# XMC4800 register map
Vendor: Infineon; File version: 1.3.0 (Reference Manual v1.3)
CPU: CM4 r2p0, little endian, MPU, FPU, 6 interrupt priority bits
Registers are 32-bit, read-write, reset 0x0 unless marked. A register's access mark holds for its fields unless they carry their own. Offsets are from the block's base; [hi:lo] are bit positions; {n}, {i} and the like mark numbered series; 'fields as' and 'values as' point back to an identical list.

## EBU — External Bus Unit
Base 0x58008000
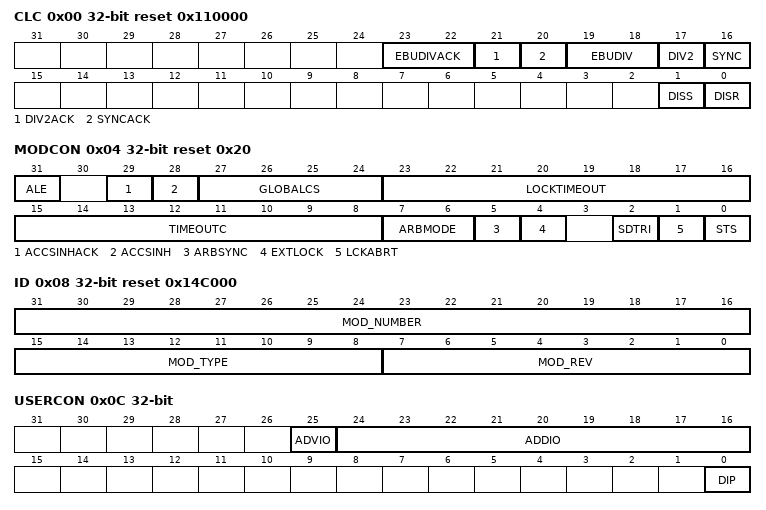
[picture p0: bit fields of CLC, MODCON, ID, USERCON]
0x00 CLC access per field reset 0x110000 — EBU Clock Control Register
  [23:22] EBUDIVACK ro — EBU Clock Divide Ratio Status
    0=EBU is running off input clock (default after reset); 1=EBU is running off input clock divided by 2; 2=EBU is running off input clock divided by 3; 3=EBU is running off input clock divided by 4
  [21] DIV2ACK ro — DIV2 Clocking Mode Status
    0=EBU is using standard clocking mode. clock input selected by SYNC bitfield (default after reset).; 1=EBU is running off AHB bus clock divided by 2
  [20] SYNCACK ro — EBU Clocking Mode Status
    0=the EBU is asynchronous to the AHB bus clock and is using a separate clock source; 1=EBU is synchronous to the AHB bus clock (default after reset)
  [19:18] EBUDIV rw — EBU Clock Divide Ratio
    0=request EBU to run off input clock (default after reset); 1=request EBU to run off input clock divided by 2; 2=request EBU to run off input clock divided by 3; 3=request EBU to run off input clock divided by 4
  [17] DIV2 rw — DIV2 Clocking Mode
    0=standard clocking mode. clock input selected by SYNC bitfield (default after reset).; 1=request EBU to run off AHB bus clock divided by 2
  [16] SYNC rw — EBU Clocking Mode
    0=request EBU to run asynchronously to AHB bus clock and use separate clock source; 1=request EBU to run synchronously to ARM processor (default after reset)
  [1] DISS ro — EBU Disable Status Bit
    0=EBU is enabled (default after reset); 1=EBU is disabled
  [0] DISR rw — EBU Disable Request Bit
    0=EBU disable is not requested; 1=EBU disable is requested
0x04 MODCON access per field reset 0x20 — EBU Configuration Register
  [31] ALE rw — ALE Mode
    0=Output is ADV; 1=Output is ALE
  [29] ACCSINHACK ro — Access inhibit acknowledge
  [28] ACCSINH rw — Access Inhibit request
  [27:24] GLOBALCS rw — Global Chip Select Enable
  [23:16] LOCKTIMEOUT rw — Lock Timeout Counter Preload
  [15:8] TIMEOUTC rw — Bus Time-out Control
    0=Time-out is disabled; 1=Time-out is generated after 1 8 clock cycles; 255=Time-out is generated after 255 8 clock cycles
  [7:6] ARBMODE rw — Arbitration Mode Selection
    0=No Bus arbitration mode selected; 1=Arbiter Mode arbitration mode selected; 2=Participant arbitration mode selected; 3=Sole Master arbitration mode selected
  [5] ARBSYNC rw — Arbitration Signal Synchronization Control
    0=Arbitration inputs are synchronous; 1=Arbitration inputs are asynchronous
  [4] EXTLOCK rw — External Bus Lock Control
    0=External bus is not locked after the EBU gains ownership; 1=External bus is locked after the EBU gains ownership
  [2] SDTRI rw — SDRAM Tristate
    0=SDRAM control signals are driven by the EBU when the EBU does not own the external bus. SDRAM cannot be shared.; 1=SDRAM control signals are tri-stated by the EBU when the EBU does not own the external bus. The SDRAM can be shared.
  [1] LCKABRT ro — Lock Abort
  [0] STS ro — Memory Status Bit
0x08 ID ro reset 0x14C000 (reset mask 0xFFFFFF00) — EBU Module Identification Register
  [31:16] MOD_NUMBER — Module Number
  [15:8] MOD_TYPE — Module Type
  [7:0] MOD_REV — Module Revision
0x0C USERCON — EBU Test/Control Configuration Register
  [25] ADVIO — ADV Pin to GPIO Mode
    0=ADV pin is required for controlling memory; 1=ADV pin is available for GPIO function
  [24:16] ADDIO — Address Pins to GPIO Mode
    0=Address Bit is required for addressing memory; 1=Address Bit is available for GPIO function
  [0] DIP — Disable Internal Pipelining
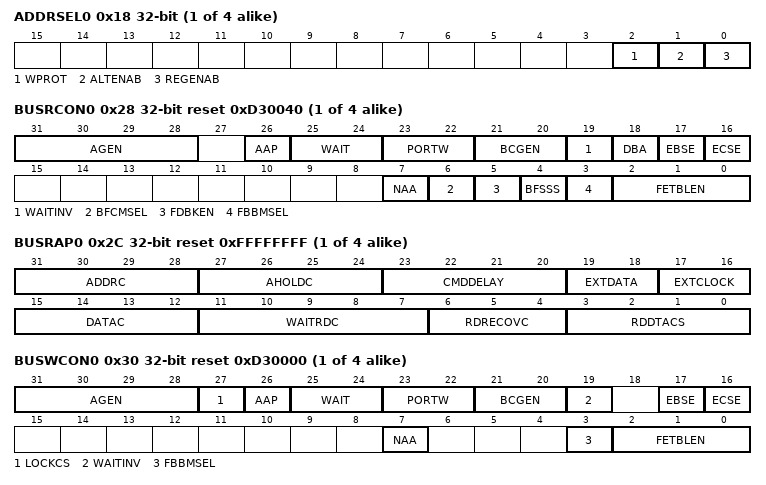
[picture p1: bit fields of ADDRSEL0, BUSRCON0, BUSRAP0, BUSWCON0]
{0x18+4i} ADDRSEL{i} (i=0..3) — EBU Address Select Register {i}
  [2] WPROT — Memory Region Write Protect
    0=Region is enabled for write accesses; 1=Region is write protected
  [1] ALTENAB — Alternate Region Enable
    0=Memory region is disabled (default after reset); 1=Memory region is enabled
  [0] REGENAB — Memory Region Enable
    values as ALTENAB
{0x28+0x10*i} BUSRCON{i} reset 0xD30040 (i=0..3) — EBU Bus Configuration Register
  [31:28] AGEN — Device Type for Region
  [26] AAP — Asynchronous Address phase:
    0=Clock is enabled at beginning of access; 1=Clock is enabled at after address phase
  [25:24] WAIT — External Wait Control: 0=OFF (default after reset)., 1=Asynchronous input at WAIT., 2=Synchronous input at WAIT., 3=reserved., 0=OFF (default after reset)., 1=Wait for page load (Early WAIT)., 2=Wait for page load (WAIT with data)., 3=Abort and retry access.,
  [23:22] PORTW — Device Addressing Mode
  [21:20] BCGEN — Byte Control Signal Control
    0=Byte control signals follow chip select timing; 1=Byte control signals follow control signal timing (RD, RD/WR) (default after reset); 2=Byte control signals follow write enable signal timing (RD/WR only)
  [19] WAITINV — Reversed polarity at WAIT
    0=input at WAIT pin is active low (default after reset); 1=input at WAIT pin is active high
  [18] DBA — Disable Burst Address Wrapping
    0=Memory Controller automatically re-aligns any non-aligned synchronous burst access so that data can be fetched from the device in a single burst transaction; 1=Memory Controller always starts any burst access to a synchronous burst device at the address specified by the AHB request. Any required address wrapping must be automatically provided by the Burst FLASH device.
  [17] EBSE — Early Burst Signal Enable for Synchronous Burst
    0=ADV is delayed; 1=ADV is not delayed
  [16] ECSE — Early Chip Select for Synchronous Burst
    0=CS is delayed; 1=CS is not delayed
  [7] NAA — Enable flash non-array access workaround
  [6] BFCMSEL — Burst Flash Clock Mode Select
    0=Burst Flash Clock runs continuously with values selected by this register; 1=Burst Flash Clock is disabled between accesses
  [5] FDBKEN — Burst FLASH Clock Feedback Enable
    0=BFCLK feedback not used; 1=Incoming data and control signals (from the Burst FLASH device) are re-synchronized to the BFCLKI input
  [4] BFSSS — Read Single Stage Synchronization:
    0=Two stages of synchronization used. (maximum margin); 1=One stage of synchronization used. (minimum latency)
  [3] FBBMSEL — Synchronous burst buffer mode select
    0=Burst buffer length defined by value in FETBLEN (default after reset); 1=Continuous mode. All data required for transaction is transferred in a single burst.
  [2:0] FETBLEN — Burst Length for Synchronous Burst
    0=1 data access (default after reset); 1=2 data accesses; 2=4 data accesses; 3=8 data accesses
{0x2C+0x10*i} BUSRAP{i} reset 0xFFFFFFFF (i=0..3) — EBU Bus Read Access Parameter Register
  [31:28] ADDRC — Address Cycles
    0=1 clock cycle selected; 1=1 clock cycle selected; 14=14 clock cycles selected; 15=15 clock cycles selected
  [27:24] AHOLDC — Address Hold Cycles
    0=0 clock cycle selected; 1=1 clock cycle selected; 14=14 clock cycles selected; 15=15 clock cycles selected
  [23:20] CMDDELAY — Command Delay Cycles
    values as AHOLDC
  [19:18] EXTDATA — Extended data
    0=external memory outputs data every BFCLK cycle; 1=external memory outputs data every two BFCLK cycles; 2=external memory outputs data every four BFCLK cycles; 3=external memory outputs data every eight BFCLK cycles
  [17:16] EXTCLOCK — Frequency of external clock at pin BFCLKO
    0=Equal to INT_CLK frequency; 1=1/2 of INT_CLK frequency; 2=1/3 of INT_CLK frequency; 3=1/4 of INT_CLK frequency (default after reset)
  [15:12] DATAC — Data Hold Cycles for Read Accesses
  [11:7] WAITRDC — Programmed Wait States for read accesses
    0=1 wait state; 1=1 wait states; 2=2 wait state; 30=30 wait states; 31=31 wait states
  [6:4] RDRECOVC — Recovery Cycles after Read Accesses
    0=No Recovery Phase clock cycles available; 1=1 clock cycle selected; 6=6 clock cycles selected; 7=7 clock cycles selected
  [3:0] RDDTACS — Recovery Cycles between Different Regions
    0=No Recovery Phase clock cycles available; 1=1 clock cycle selected; 14=14 clock cycles selected; 15=15 clock cycles selected
{0x30+0x10*i} BUSWCON{i} access per field reset 0xD30000 (i=0..3) — EBU Bus Write Configuration Register
  [31:28] AGEN rw — Device Type for Region
  [27] LOCKCS rw — Lock Chip Select
    0=Chip Select cannot be locked (default after reset); 1=Chip Select will be automatically locked when written to from the processor data port
  [26] AAP rw — Asynchronous Address phase:
    values as BUSRCON0.AAP
  [25:24] WAIT rw — External Wait Control: 0=OFF (default after reset)., 1=Asynchronous input at WAIT., 2=Synchronous input at WAIT., 3=reserved., 0=OFF (default after reset)., 1=Wait for page load (Early WAIT)., 2=Wait for page load (WAIT with data)., 3=Abort and retry access.,
  [23:22] PORTW ro — Device Addressing Mode
  [21:20] BCGEN rw — Byte Control Signal Control
    values as BUSRCON0.BCGEN
  [19] WAITINV rw — Reversed polarity at WAIT
    values as BUSRCON0.WAITINV
  [17] EBSE rw — Early Burst Signal Enable for Synchronous Burst
    0=ADV is delayed; 1=ADV is not delayed
  [16] ECSE rw — Early Chip Select for Synchronous Burst
    0=CS is delayed; 1=CS is not delayed
  [7] NAA ro — Enable flash non-array access workaround
  [3] FBBMSEL rw — Synchronous burst buffer mode select
    0=Burst buffer length defined by value in FETBLEN (default after reset); 1=Continuous mode. All data required for transaction transferred in single burst
  [2:0] FETBLEN rw — Burst Length for Synchronous Burst
    values as BUSRCON0.FETBLEN
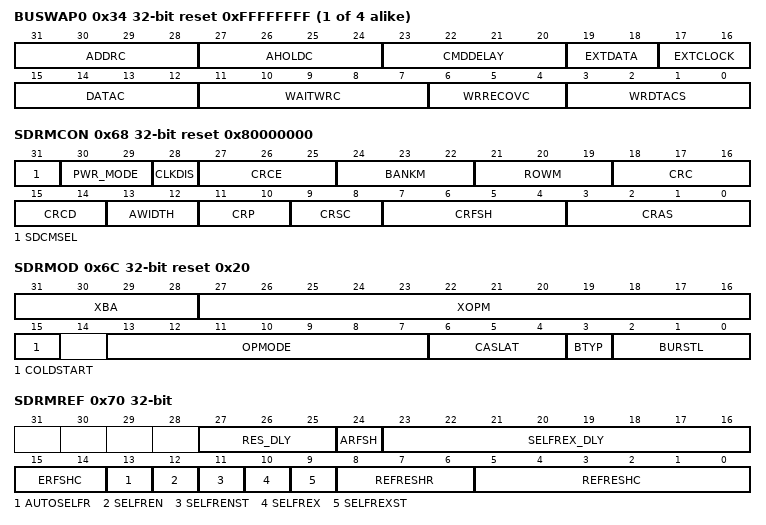
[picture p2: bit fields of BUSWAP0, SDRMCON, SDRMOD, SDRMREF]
{0x34+0x10*i} BUSWAP{i} reset 0xFFFFFFFF (i=0..3) — EBU Bus Write Access Parameter Register
  [31:28] ADDRC — Address Cycles
    values as BUSRAP0.ADDRC
  [27:24] AHOLDC — Address Hold Cycles
    values as BUSRAP0.AHOLDC
  [23:20] CMDDELAY — Command Delay Cycles
    values as BUSRAP0.AHOLDC
  [19:18] EXTDATA — Extended data
    values as BUSRAP0.EXTDATA
  [17:16] EXTCLOCK — Frequency of external clock at pin BFCLKO
    values as BUSRAP0.EXTCLOCK
  [15:12] DATAC — Data Hold Cycles for Write Accesses
    values as BUSRAP0.RDDTACS
  [11:7] WAITWRC — Programmed Wait States for write accesses
    values as BUSRAP0.WAITRDC
  [6:4] WRRECOVC — Recovery Cycles after Write Accesses
    values as BUSRAP0.RDRECOVC
  [3:0] WRDTACS — Recovery Cycles between Different Regions
    values as BUSRAP0.RDDTACS
0x68 SDRMCON reset 0x80000000 — EBU SDRAM Control Register
  [31] SDCMSEL — SDRAM clock mode select
    1=clock disabled between accesses; 0=clock continuously runs
  [30:29] PWR_MODE — Power Save Mode used for gated clock mode
    0=precharge before clock stop (default after reset); 1=auto-precharge before clock stop; 2=active power down (stop clock without precharge); 3=clock stop power down
  [28] CLKDIS — Disable SDRAM clock output
    0=clock enabled; 1=clock disabled
  [27:25] CRCE — Row cycle time counter extension
  [24:22] BANKM — Mask for bank tag
    {v}=Address bit {v+20} to {v+19} (v=1..6); 7=Address bit 26
  [21:19] ROWM — Mask for row tag
    {v}=Address bit 26 to {v+8} (v=1..5)
  [18:16] CRC — Row cycle time counter
  [15:14] CRCD — Row to column delay counter
  [13:12] AWIDTH — Width of column address
    0=do not use; 1=Address(8:0); 2=Address(9:0); 3=Address(10:0)
  [11:10] CRP — Row precharge time counter
  [9:8] CRSC — Mode register set-up time
  [7:4] CRFSH — Initialization refresh commands counter
  [3:0] CRAS — Row to precharge delay counter
0x6C SDRMOD access per field reset 0x20 — EBU SDRAM Mode Register
  [31:28] XBA rw — Extended Operation Bank Select
  [27:16] XOPM rw — Extended Operation Mode
  [15] COLDSTART wo — SDRAM coldstart
  [13:7] OPMODE rw — Operation Mode
    0=Only this value must be written (default after reset)
  [6:4] CASLAT rw — CAS latency
    2=Two clocks (default after reset); 3=Three clocks
  [3] BTYP rw — Burst type
    0=Only this value should be written (default after reset)
  [2:0] BURSTL rw — Burst length
    0=1 (default after reset); 1=2; 2=4; 3=8; 4=16
0x70 SDRMREF access per field — EBU SDRAM Refresh Control Register
  [27:25] RES_DLY rw — Delay on Power Down Exit
  [24] ARFSH rw — Auto Refresh on Self refresh Exit
  [23:16] SELFREX_DLY rw — Self Refresh Exit Delay
  [15:14] ERFSHC rw — Extended Refresh Counter Period
  [13] AUTOSELFR rw — Automatic Self Refresh
  [12] SELFREN rw — Self Refresh Entry
  [11] SELFRENST ro — Self Refresh Entry Status.
  [10] SELFREX rw — Self Refresh Exit (Power Up).
  [9] SELFREXST ro — Self Refresh Exit Status.
  [8:6] REFRESHR rw — Number of refresh commands
  [5:0] REFRESHC rw — Refresh counter period
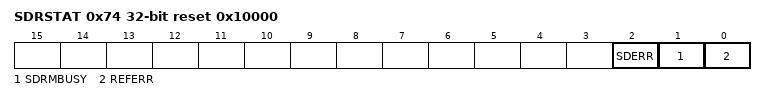
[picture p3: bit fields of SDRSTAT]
0x74 SDRSTAT ro reset 0x10000 — EBU SDRAM Status Register
  [2] SDERR — SDRAM read error
    0=Reads running successfully; 1=Read error condition has been detected
  [1] SDRMBUSY — SDRAM Busy
    0=Power-up initialization sequence is not running; 1=Power-up initialization sequence is running
  [0] REFERR — SDRAM Refresh Error
    0=No refresh error; 1=Refresh error occurred
